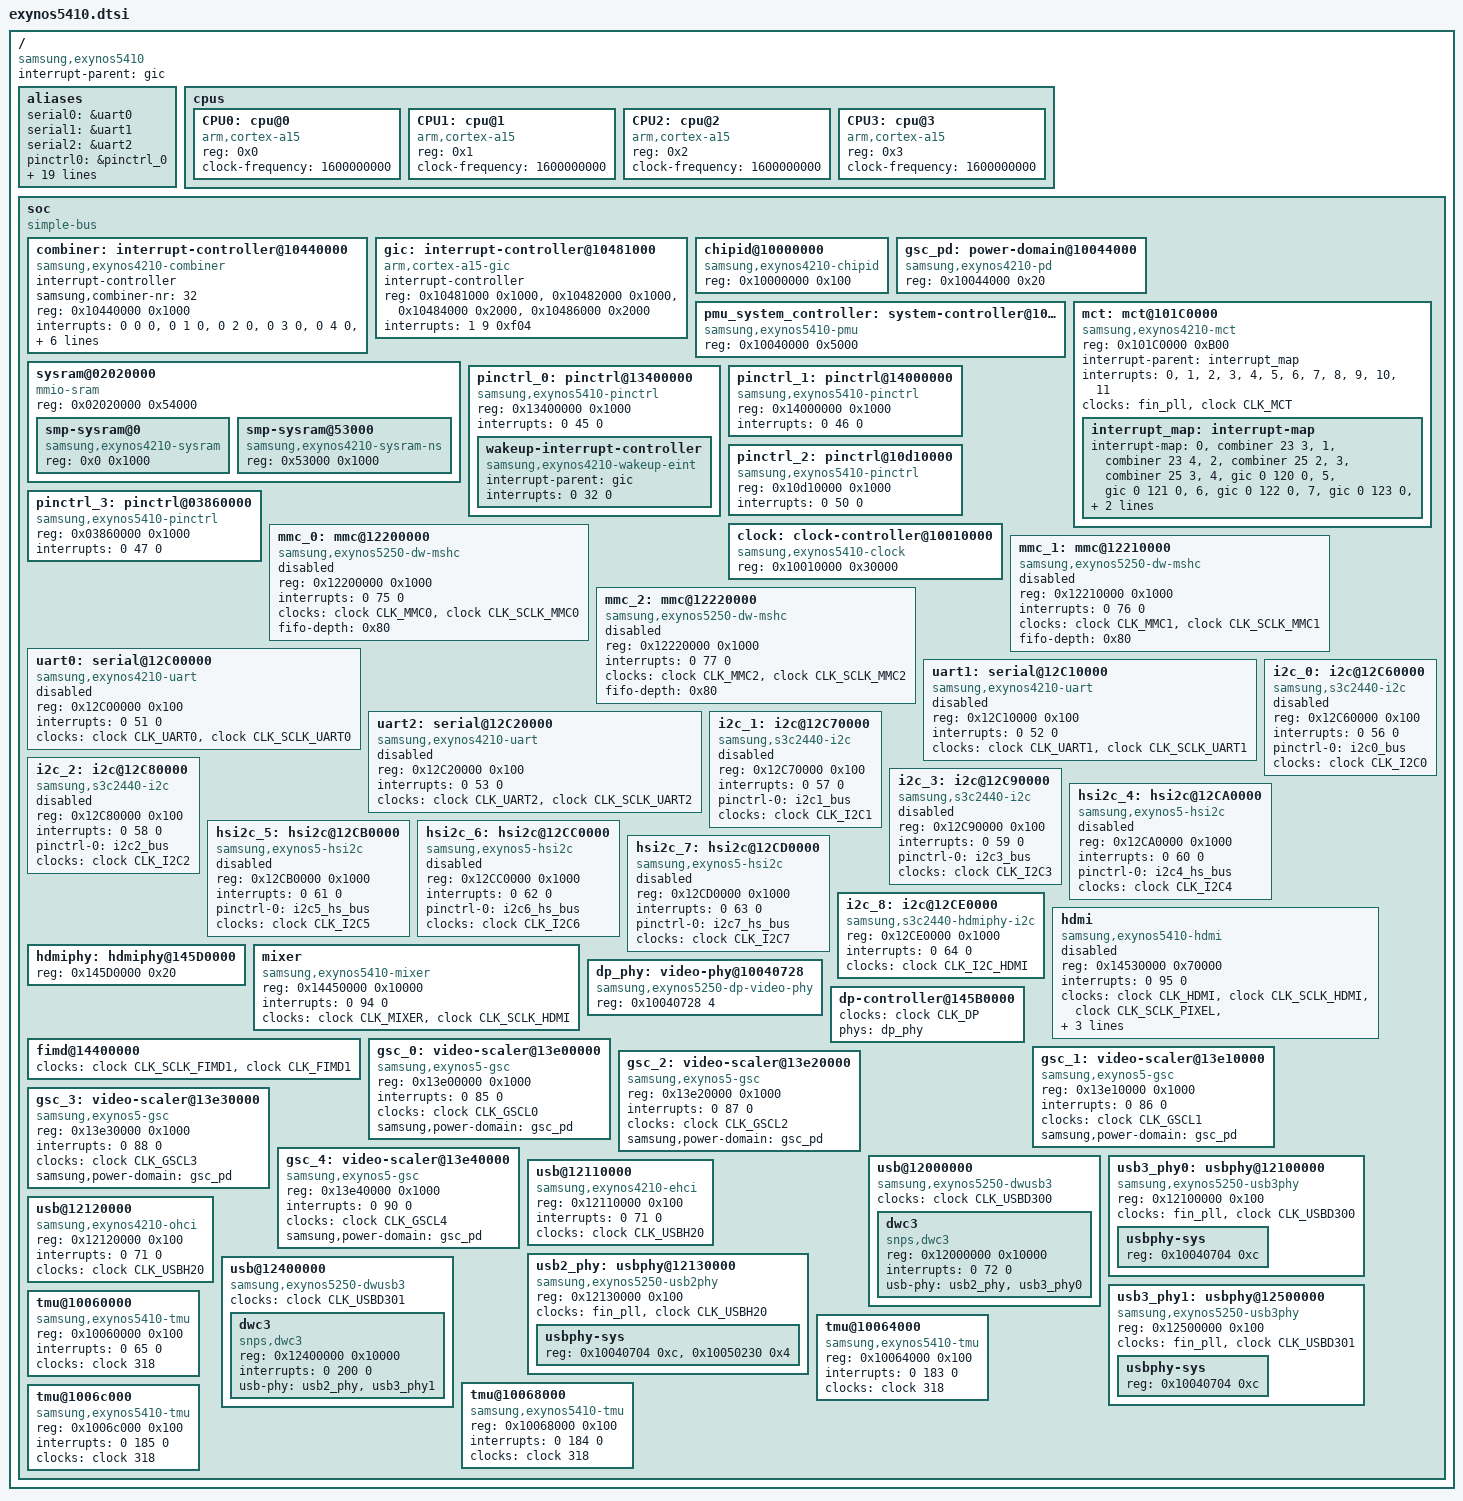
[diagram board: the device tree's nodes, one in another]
/*
 * SAMSUNG EXYNOS5410 SoC device tree source
 *
 * Copyright (c) 2013 Samsung Electronics Co., Ltd.
 *		http://www.samsung.com
 *
 * SAMSUNG EXYNOS5410 SoC device nodes are listed in this file.
 * EXYNOS5410 based board files can include this file and provide
 * values for board specfic bindings.
 *
 * This program is free software; you can redistribute it and/or modify
 * it under the terms of the GNU General Public License version 2 as
 * published by the Free Software Foundation.
 */

#include "skeleton.dtsi"
#include <dt-bindings/clock/exynos5410.h>

/ {
	compatible = "samsung,exynos5410", "samsung,exynos5";
	interrupt-parent = <&gic>;

	aliases {
		serial0 = &uart0;
		serial1 = &uart1;
		serial2 = &uart2;
	};

	aliases {
		pinctrl0 = &pinctrl_0;
		pinctrl1 = &pinctrl_1;
		pinctrl2 = &pinctrl_2;
		pinctrl3 = &pinctrl_3;
	};

	aliases {
		i2c0 = &i2c_0;
		i2c1 = &i2c_1;
		i2c2 = &i2c_2;
		i2c3 = &i2c_3;
		i2c4 = &hsi2c_4;
		i2c5 = &hsi2c_5;
		i2c6 = &hsi2c_6;
		i2c7 = &hsi2c_7;
		i2c8 = &i2c_8;
	};

	aliases {
		gsc0 = &gsc_0;
		gsc1 = &gsc_1;
		gsc2 = &gsc_2;
		gsc3 = &gsc_3;
		gsc4 = &gsc_4;
	};

	aliases {
		usb3phy0 = &usb3_phy0;
		usb3phy1 = &usb3_phy1;
	};

	cpus {
		#address-cells = <1>;
		#size-cells = <0>;

		CPU0: cpu@0 {
			device_type = "cpu";
			compatible = "arm,cortex-a15";
			reg = <0x0>;
			clock-frequency = <1600000000>;
		};

		CPU1: cpu@1 {
			device_type = "cpu";
			compatible = "arm,cortex-a15";
			reg = <0x1>;
			clock-frequency = <1600000000>;
		};

		CPU2: cpu@2 {
			device_type = "cpu";
			compatible = "arm,cortex-a15";
			reg = <0x2>;
			clock-frequency = <1600000000>;
		};

		CPU3: cpu@3 {
			device_type = "cpu";
			compatible = "arm,cortex-a15";
			reg = <0x3>;
			clock-frequency = <1600000000>;
		};
	};

	soc: soc {
		compatible = "simple-bus";
		#address-cells = <1>;
		#size-cells = <1>;
		ranges;

		combiner: interrupt-controller@10440000 {
			compatible = "samsung,exynos4210-combiner";
			#interrupt-cells = <2>;
			interrupt-controller;
			samsung,combiner-nr = <32>;
			reg = <0x10440000 0x1000>;
			interrupts =	<0 0 0>, <0 1 0>, <0 2 0>, <0 3 0>,
					<0 4 0>, <0 5 0>, <0 6 0>, <0 7 0>,
					<0 8 0>, <0 9 0>, <0 10 0>, <0 11 0>,
					<0 12 0>, <0 13 0>, <0 14 0>, <0 15 0>,
					<0 16 0>, <0 17 0>, <0 18 0>, <0 19 0>,
					<0 20 0>, <0 21 0>, <0 22 0>, <0 23 0>,
					<0 24 0>, <0 25 0>, <0 26 0>, <0 27 0>,
					<0 28 0>, <0 29 0>, <0 30 0>, <0 31 0>;
		};

		gic: interrupt-controller@10481000 {
			compatible = "arm,cortex-a15-gic", "arm,cortex-a9-gic";
			#interrupt-cells = <3>;
			interrupt-controller;
			reg =	<0x10481000 0x1000>,
				<0x10482000 0x1000>,
				<0x10484000 0x2000>,
				<0x10486000 0x2000>;
			interrupts = <1 9 0xf04>;
		};

		chipid@10000000 {
			compatible = "samsung,exynos4210-chipid";
			reg = <0x10000000 0x100>;
		};

		gsc_pd: power-domain@10044000 {
			compatible = "samsung,exynos4210-pd";
			reg = <0x10044000 0x20>;
		};

		pmu_system_controller: system-controller@10040000 {
			compatible = "samsung,exynos5410-pmu", "syscon";
			reg = <0x10040000 0x5000>;
		};

		mct: mct@101C0000 {
			compatible = "samsung,exynos4210-mct";
			reg = <0x101C0000 0xB00>;
			interrupt-parent = <&interrupt_map>;
			interrupts = <0>, <1>, <2>, <3>,
				<4>, <5>, <6>, <7>,
				<8>, <9>, <10>, <11>;
			clocks = <&fin_pll>, <&clock CLK_MCT>;
			clock-names = "fin_pll", "mct";

			interrupt_map: interrupt-map {
				#interrupt-cells = <1>;
				#address-cells = <0>;
				#size-cells = <0>;
				interrupt-map = <0 &combiner 23 3>,
						<1 &combiner 23 4>,
						<2 &combiner 25 2>,
						<3 &combiner 25 3>,
						<4 &gic 0 120 0>,
						<5 &gic 0 121 0>,
						<6 &gic 0 122 0>,
						<7 &gic 0 123 0>,
						<8 &gic 0 128 0>,
						<9 &gic 0 129 0>,
						<10 &gic 0 130 0>,
						<11 &gic 0 131 0>;
			};
		};

		sysram@02020000 {
			compatible = "mmio-sram";
			reg = <0x02020000 0x54000>;
			#address-cells = <1>;
			#size-cells = <1>;
			ranges = <0 0x02020000 0x54000>;

			smp-sysram@0 {
				compatible = "samsung,exynos4210-sysram";
				reg = <0x0 0x1000>;
			};

			smp-sysram@53000 {
				compatible = "samsung,exynos4210-sysram-ns";
				reg = <0x53000 0x1000>;
			};
		};

		pinctrl_0: pinctrl@13400000 {
			compatible = "samsung,exynos5410-pinctrl";
			reg = <0x13400000 0x1000>;
			interrupts = <0 45 0>;

			wakeup-interrupt-controller {
				compatible = "samsung,exynos4210-wakeup-eint";
				interrupt-parent = <&gic>;
				interrupts = <0 32 0>;
			};
		};

		pinctrl_1: pinctrl@14000000 {
			compatible = "samsung,exynos5410-pinctrl";
			reg = <0x14000000 0x1000>;
			interrupts = <0 46 0>;
		};

		pinctrl_2: pinctrl@10d10000 {
			compatible = "samsung,exynos5410-pinctrl";
			reg = <0x10d10000 0x1000>;
			interrupts = <0 50 0>;
		};

		pinctrl_3: pinctrl@03860000 {
			compatible = "samsung,exynos5410-pinctrl";
			reg = <0x03860000 0x1000>;
			interrupts = <0 47 0>;
		};

		clock: clock-controller@10010000 {
			compatible = "samsung,exynos5410-clock";
			reg = <0x10010000 0x30000>;
			#clock-cells = <1>;
		};

		mmc_0: mmc@12200000 {
			compatible = "samsung,exynos5250-dw-mshc";
			reg = <0x12200000 0x1000>;
			interrupts = <0 75 0>;
			#address-cells = <1>;
			#size-cells = <0>;
			clocks = <&clock CLK_MMC0>, <&clock CLK_SCLK_MMC0>;
			clock-names = "biu", "ciu";
			fifo-depth = <0x80>;
			status = "disabled";
		};

		mmc_1: mmc@12210000 {
			compatible = "samsung,exynos5250-dw-mshc";
			reg = <0x12210000 0x1000>;
			interrupts = <0 76 0>;
			#address-cells = <1>;
			#size-cells = <0>;
			clocks = <&clock CLK_MMC1>, <&clock CLK_SCLK_MMC1>;
			clock-names = "biu", "ciu";
			fifo-depth = <0x80>;
			status = "disabled";
		};

		mmc_2: mmc@12220000 {
			compatible = "samsung,exynos5250-dw-mshc";
			reg = <0x12220000 0x1000>;
			interrupts = <0 77 0>;
			#address-cells = <1>;
			#size-cells = <0>;
			clocks = <&clock CLK_MMC2>, <&clock CLK_SCLK_MMC2>;
			clock-names = "biu", "ciu";
			fifo-depth = <0x80>;
			status = "disabled";
		};

		uart0: serial@12C00000 {
			compatible = "samsung,exynos4210-uart";
			reg = <0x12C00000 0x100>;
			interrupts = <0 51 0>;
			clocks = <&clock CLK_UART0>, <&clock CLK_SCLK_UART0>;
			clock-names = "uart", "clk_uart_baud0";
			status = "disabled";
		};

		uart1: serial@12C10000 {
			compatible = "samsung,exynos4210-uart";
			reg = <0x12C10000 0x100>;
			interrupts = <0 52 0>;
			clocks = <&clock CLK_UART1>, <&clock CLK_SCLK_UART1>;
			clock-names = "uart", "clk_uart_baud0";
			status = "disabled";
		};

		uart2: serial@12C20000 {
			compatible = "samsung,exynos4210-uart";
			reg = <0x12C20000 0x100>;
			interrupts = <0 53 0>;
			clocks = <&clock CLK_UART2>, <&clock CLK_SCLK_UART2>;
			clock-names = "uart", "clk_uart_baud0";
			status = "disabled";
		};

		i2c_0: i2c@12C60000 {
			compatible = "samsung,s3c2440-i2c";
			reg = <0x12C60000 0x100>;
			interrupts = <0 56 0>;
			#address-cells = <1>;
			#size-cells = <0>;
			pinctrl-names = "default";
			pinctrl-0 = <&i2c0_bus>;
			clocks = <&clock CLK_I2C0>;
			clock-names = "i2c";
			status = "disabled";
		};

		i2c_1: i2c@12C70000 {
			compatible = "samsung,s3c2440-i2c";
			reg = <0x12C70000 0x100>;
			interrupts = <0 57 0>;
			#address-cells = <1>;
			#size-cells = <0>;
			pinctrl-names = "default";
			pinctrl-0 = <&i2c1_bus>;
			clocks = <&clock CLK_I2C1>;
			clock-names = "i2c";
			status = "disabled";
		};

		i2c_2: i2c@12C80000 {
			compatible = "samsung,s3c2440-i2c";
			reg = <0x12C80000 0x100>;
			interrupts = <0 58 0>;
			#address-cells = <1>;
			#size-cells = <0>;
			pinctrl-names = "default";
			pinctrl-0 = <&i2c2_bus>;
			clocks = <&clock CLK_I2C2>;
			clock-names = "i2c";
			status = "disabled";
		};

		i2c_3: i2c@12C90000 {
			compatible = "samsung,s3c2440-i2c";
			reg = <0x12C90000 0x100>;
			interrupts = <0 59 0>;
			#address-cells = <1>;
			#size-cells = <0>;
			pinctrl-names = "default";
			pinctrl-0 = <&i2c3_bus>;
			clocks = <&clock CLK_I2C3>;
			clock-names = "i2c";
			status = "disabled";
		};

		hsi2c_4: hsi2c@12CA0000 {
			compatible = "samsung,exynos5-hsi2c";
			reg = <0x12CA0000 0x1000>;
			interrupts = <0 60 0>;
			#address-cells = <1>;
			#size-cells = <0>;
			pinctrl-names = "default";
			pinctrl-0 = <&i2c4_hs_bus>;
			clocks = <&clock CLK_I2C4>;
			clock-names = "hsi2c";
			status = "disabled";
		};

		hsi2c_5: hsi2c@12CB0000 {
			compatible = "samsung,exynos5-hsi2c";
			reg = <0x12CB0000 0x1000>;
			interrupts = <0 61 0>;
			#address-cells = <1>;
			#size-cells = <0>;
			pinctrl-names = "default";
			pinctrl-0 = <&i2c5_hs_bus>;
			clocks = <&clock CLK_I2C5>;
			clock-names = "hsi2c";
			status = "disabled";
		};

		hsi2c_6: hsi2c@12CC0000 {
			compatible = "samsung,exynos5-hsi2c";
			reg = <0x12CC0000 0x1000>;
			interrupts = <0 62 0>;
			#address-cells = <1>;
			#size-cells = <0>;
			pinctrl-names = "default";
			pinctrl-0 = <&i2c6_hs_bus>;
			clocks = <&clock CLK_I2C6>;
			clock-names = "hsi2c";
			status = "disabled";
		};

		hsi2c_7: hsi2c@12CD0000 {
			compatible = "samsung,exynos5-hsi2c";
			reg = <0x12CD0000 0x1000>;
			interrupts = <0 63 0>;
			#address-cells = <1>;
			#size-cells = <0>;
			pinctrl-names = "default";
			pinctrl-0 = <&i2c7_hs_bus>;
			clocks = <&clock CLK_I2C7>;
			clock-names = "hsi2c";
			status = "disabled";
		};

		i2c_8: i2c@12CE0000 {
			compatible = "samsung,s3c2440-hdmiphy-i2c";
			reg = <0x12CE0000 0x1000>;
			interrupts = <0 64 0>;
			#address-cells = <1>;
			#size-cells = <0>;
			clocks = <&clock CLK_I2C_HDMI>;
			clock-names = "i2c";
		};

		hdmi: hdmi {
			compatible = "samsung,exynos5410-hdmi";
			reg = <0x14530000 0x70000>;
			interrupts = <0 95 0>;
			clocks = <&clock CLK_HDMI>, <&clock CLK_SCLK_HDMI>,
				 <&clock CLK_SCLK_PIXEL>,
				 <&clock CLK_SCLK_HDMIPHY>,
				<&clock CLK_MOUT_HDMI>;
			clock-names = "hdmi", "sclk_hdmi", "sclk_pixel",
					"sclk_hdmiphy", "mout_hdmi";
			phy = <&hdmiphy>;
			samsung,syscon-phandle = <&pmu_system_controller>;
			status = "disabled";
		};

		hdmiphy: hdmiphy@145D0000 {
			reg = <0x145D0000 0x20>;
		};

		mixer {
			compatible = "samsung,exynos5410-mixer";
			reg = <0x14450000 0x10000>;
			interrupts = <0 94 0>;
			clocks = <&clock CLK_MIXER>, <&clock CLK_SCLK_HDMI>;
			clock-names = "mixer", "sclk_hdmi";
		};

		dp_phy: video-phy@10040728 {
			compatible = "samsung,exynos5250-dp-video-phy";
			reg = <0x10040728 4>;
			#phy-cells = <0>;
		};

		dp-controller@145B0000 {
			clocks = <&clock CLK_DP>;
			clock-names = "dp";
			phys = <&dp_phy>;
			phy-names = "dp";
		};

		fimd@14400000 {
			/* samsung,power-domain = <&disp_pd>; */
			clocks = <&clock CLK_SCLK_FIMD1>, <&clock CLK_FIMD1>;
			clock-names = "sclk_fimd", "fimd";
		};

		gsc_0: video-scaler@13e00000 {
			compatible = "samsung,exynos5-gsc";
			reg = <0x13e00000 0x1000>;
			interrupts = <0 85 0>;
			clocks = <&clock CLK_GSCL0>;
			clock-names = "gscl";
			samsung,power-domain = <&gsc_pd>;
		};

		gsc_1: video-scaler@13e10000 {
			compatible = "samsung,exynos5-gsc";
			reg = <0x13e10000 0x1000>;
			interrupts = <0 86 0>;
			clocks = <&clock CLK_GSCL1>;
			clock-names = "gscl";
			samsung,power-domain = <&gsc_pd>;
		};

		gsc_2: video-scaler@13e20000 {
			compatible = "samsung,exynos5-gsc";
			reg = <0x13e20000 0x1000>;
			interrupts = <0 87 0>;
			clocks = <&clock CLK_GSCL2>;
			clock-names = "gscl";
			samsung,power-domain = <&gsc_pd>;
		};

		gsc_3: video-scaler@13e30000 {
			compatible = "samsung,exynos5-gsc";
			reg = <0x13e30000 0x1000>;
			interrupts = <0 88 0>;
			clocks = <&clock CLK_GSCL3>;
			clock-names = "gscl";
			samsung,power-domain = <&gsc_pd>;
		};

		gsc_4: video-scaler@13e40000 {
			compatible = "samsung,exynos5-gsc";
			reg = <0x13e40000 0x1000>;
			interrupts = <0 90 0>;
			clocks = <&clock CLK_GSCL4>;
			clock-names = "gscl";
			samsung,power-domain = <&gsc_pd>;
		};

		usb@12000000 {
			compatible = "samsung,exynos5250-dwusb3";
			clocks = <&clock CLK_USBD300>;
			clock-names = "usbdrd30";
			#address-cells = <1>;
			#size-cells = <1>;
			ranges;

			dwc3 {
				compatible = "snps,dwc3";
				reg = <0x12000000 0x10000>;
				interrupts = <0 72 0>;
				usb-phy = <&usb2_phy>, <&usb3_phy0>;
			};
		};

		usb3_phy0: usbphy@12100000 {
			compatible = "samsung,exynos5250-usb3phy";
			reg = <0x12100000 0x100>;
			clocks = <&fin_pll>, <&clock CLK_USBD300>;
			clock-names = "ext_xtal", "usbdrd30";
			#address-cells = <1>;
			#size-cells = <1>;
			ranges;

			usbphy-sys {
				reg = <0x10040704 0xc>;
			};
		};

		usb@12110000 {
			compatible = "samsung,exynos4210-ehci";
			reg = <0x12110000 0x100>;
			interrupts = <0 71 0>;

			clocks = <&clock CLK_USBH20>;
			clock-names = "usbhost";
		};

		usb@12120000 {
			compatible = "samsung,exynos4210-ohci";
			reg = <0x12120000 0x100>;
			interrupts = <0 71 0>;

			clocks = <&clock CLK_USBH20>;
			clock-names = "usbhost";
		};

		usb2_phy: usbphy@12130000 {
			compatible = "samsung,exynos5250-usb2phy";
			reg = <0x12130000 0x100>;
			clocks = <&fin_pll>, <&clock CLK_USBH20>;
			clock-names = "ext_xtal", "usbhost";
			#address-cells = <1>;
			#size-cells = <1>;
			ranges;

			usbphy-sys {
				reg = <0x10040704 0xc>,
				      <0x10050230 0x4>;
			};
		};

		usb@12400000 {
			compatible = "samsung,exynos5250-dwusb3";
			clocks = <&clock CLK_USBD301>;
			clock-names = "usbdrd30";
			#address-cells = <1>;
			#size-cells = <1>;
			ranges;

			dwc3 {
				compatible = "snps,dwc3";
				reg = <0x12400000 0x10000>;
				interrupts = <0 200 0>;
				usb-phy = <&usb2_phy>, <&usb3_phy1>;
			};
		};

		usb3_phy1: usbphy@12500000 {
			compatible = "samsung,exynos5250-usb3phy";
			reg = <0x12500000 0x100>;
			clocks = <&fin_pll>, <&clock CLK_USBD301>;
			clock-names = "ext_xtal", "usbdrd30";
			#address-cells = <1>;
			#size-cells = <1>;
			ranges;

			usbphy-sys {
				reg = <0x10040704 0xc>;
			};
		};

		/* tmu for CPU0 */
		tmu@10060000 {
			compatible = "samsung,exynos5410-tmu";
			reg = <0x10060000 0x100>;
			interrupts = <0 65 0>;
			clocks = <&clock 318>;
			clock-names = "tmu_apbif";
		};

		/* tmu for CPU1 */
		tmu@10064000 {
			compatible = "samsung,exynos5410-tmu";
			reg = <0x10064000 0x100>;
			interrupts = <0 183 0>;
			clocks = <&clock 318>;
			clock-names = "tmu_apbif";
		};

		/* tmu for CPU2 */
		tmu@10068000 {
			compatible = "samsung,exynos5410-tmu";
			reg = <0x10068000 0x100>;
			interrupts = <0 184 0>;
			clocks = <&clock 318>;
			clock-names = "tmu_apbif";
		};

		/* tmu for CPU3 */
		tmu@1006c000 {
			compatible = "samsung,exynos5410-tmu";
			reg = <0x1006c000 0x100>;
			interrupts = <0 185 0>;
			clocks = <&clock 318>;
			clock-names = "tmu_apbif";
		};
	};
};

#include "exynos5410-pinctrl.dtsi"
